# ECC_AGGR5_ECC_AGGR register map
Vendor: Texas Instruments
Peripheral module from a debugger description file (folder J721S2).
Registers are 32-bit, access not given, reset 0x0 unless marked. A register's access mark holds for its fields unless they carry their own. Offsets are as the file gives them; lines under a group give offsets from that group; [hi:lo] are bit positions; {n}, {i} and the like mark numbered series; 'fields as' and 'values as' point back to an identical list; <NAME> marks a mode.

## ECC_AGGR5_ECC_AGGR
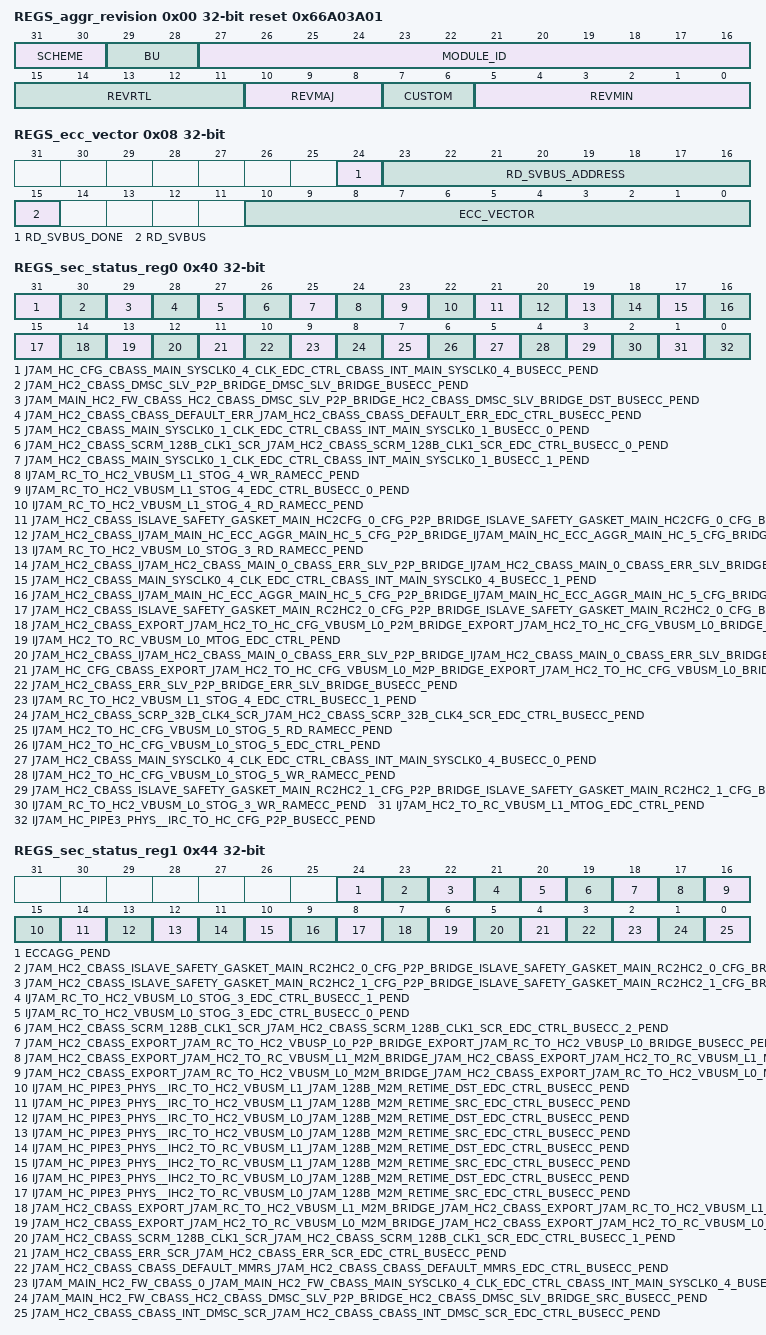
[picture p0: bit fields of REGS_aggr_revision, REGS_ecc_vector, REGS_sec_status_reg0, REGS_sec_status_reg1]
0x00 REGS_aggr_revision ro reset 0x66A03A01 — Revision parameters
  [31:30] SCHEME
  [29:28] BU
  [27:16] MODULE_ID
  [15:11] REVRTL — RTL version
  [10:8] REVMAJ — Major version
  [7:6] CUSTOM — Custom version
  [5:0] REVMIN — Minor version
0x08 REGS_ecc_vector — ECC Vector Register
  [24] RD_SVBUS_DONE — Status to indicate if read on serial VBUS is complete, write of any value will clear this bit. (access R/W1TC)
  [23:16] RD_SVBUS_ADDRESS rw — Read address
  [15] RD_SVBUS — Write 1 to trigger a read on the serial VBUS (access R/W1TS)
  [10:0] ECC_VECTOR rw — Value written to select the corresponding ECC RAM for control or status
0x0C REGS_misc_status ro reset 0x39 — Misc Status
  [10:0] NUM_RAMS — Indicates the number of RAMS serviced by the ECC aggregator
0x10 REGS_reserved_svbus rw — Reference other documents that contain the ECC RAM wrapper and EDC controller serial vbus register sets.
  [31:0] DATA — Serial VBUS register data
0x3C REGS_sec_eoi_reg — EOI Register
  [0] EOI_WR — EOI Register (access R/W1TS)
0x40 REGS_sec_status_reg0 — Interrupt Status Register 0
  [31] J7AM_HC_CFG_CBASS_MAIN_SYSCLK0_4_CLK_EDC_CTRL_CBASS_INT_MAIN_SYSCLK0_4_BUSECC_PEND — Interrupt Pending Status for j7am_hc_cfg_cbass_main_SYSCLK0_4_clk_edc_ctrl_cbass_int_main_SYSCLK0_4_busecc_pend (access R/W1TS)
  [30] J7AM_HC2_CBASS_DMSC_SLV_P2P_BRIDGE_DMSC_SLV_BRIDGE_BUSECC_PEND — Interrupt Pending Status for j7am_hc2_cbass_dmsc_slv_p2p_bridge_dmsc_slv_bridge_busecc_pend (access R/W1TS)
  [29] J7AM_MAIN_HC2_FW_CBASS_HC2_CBASS_DMSC_SLV_P2P_BRIDGE_HC2_CBASS_DMSC_SLV_BRIDGE_DST_BUSECC_PEND — Interrupt Pending Status for j7am_main_hc2_fw_cbass_hc2_cbass_dmsc_slv_p2p_bridge_hc2_cbass_dmsc_slv_bridge_dst_busecc_pend (access R/W1TS)
  [28] J7AM_HC2_CBASS_CBASS_DEFAULT_ERR_J7AM_HC2_CBASS_CBASS_DEFAULT_ERR_EDC_CTRL_BUSECC_PEND — Interrupt Pending Status for j7am_hc2_cbass_cbass_default_err_j7am_hc2_cbass_cbass_default_err_edc_ctrl_busecc_pend (access R/W1TS)
  [27] J7AM_HC2_CBASS_MAIN_SYSCLK0_1_CLK_EDC_CTRL_CBASS_INT_MAIN_SYSCLK0_1_BUSECC_0_PEND — Interrupt Pending Status for j7am_hc2_cbass_main_SYSCLK0_1_clk_edc_ctrl_cbass_int_main_SYSCLK0_1_busecc_0_pend (access R/W1TS)
  [26] J7AM_HC2_CBASS_SCRM_128B_CLK1_SCR_J7AM_HC2_CBASS_SCRM_128B_CLK1_SCR_EDC_CTRL_BUSECC_0_PEND — Interrupt Pending Status for j7am_hc2_cbass_scrm_128b_clk1_scr_j7am_hc2_cbass_scrm_128b_clk1_scr_edc_ctrl_busecc_0_pend (access R/W1TS)
  [25] J7AM_HC2_CBASS_MAIN_SYSCLK0_1_CLK_EDC_CTRL_CBASS_INT_MAIN_SYSCLK0_1_BUSECC_1_PEND — Interrupt Pending Status for j7am_hc2_cbass_main_SYSCLK0_1_clk_edc_ctrl_cbass_int_main_SYSCLK0_1_busecc_1_pend (access R/W1TS)
  [24] IJ7AM_RC_TO_HC2_VBUSM_L1_STOG_4_WR_RAMECC_PEND — Interrupt Pending Status for Ij7am_rc_to_hc2_vbusm_l1_stog_4_wr_ramecc_pend (access R/W1TS)
  [23] IJ7AM_RC_TO_HC2_VBUSM_L1_STOG_4_EDC_CTRL_BUSECC_0_PEND — Interrupt Pending Status for Ij7am_rc_to_hc2_vbusm_l1_stog_4_edc_ctrl_busecc_0_pend (access R/W1TS)
  [22] IJ7AM_RC_TO_HC2_VBUSM_L1_STOG_4_RD_RAMECC_PEND — Interrupt Pending Status for Ij7am_rc_to_hc2_vbusm_l1_stog_4_rd_ramecc_pend (access R/W1TS)
  [21] J7AM_HC2_CBASS_ISLAVE_SAFETY_GASKET_MAIN_HC2CFG_0_CFG_P2P_BRIDGE_ISLAVE_SAFETY_GASKET_MAIN_HC2CFG_0_CFG_BRIDGE_BUSECC_PEND — Interrupt Pending Status for j7am_hc2_cbass_Islave_safety_gasket_main_hc2cfg_0_cfg_p2p_bridge_Islave_safety_gasket_main_hc2cfg_0_cfg_bridge_busecc_pend (access R/W1TS)
  [20] J7AM_HC2_CBASS_IJ7AM_MAIN_HC_ECC_AGGR_MAIN_HC_5_CFG_P2P_BRIDGE_IJ7AM_MAIN_HC_ECC_AGGR_MAIN_HC_5_CFG_BRIDGE_DST_BUSECC_PEND — Interrupt Pending Status for j7am_hc2_cbass_Ij7am_main_hc_ecc_aggr_main_hc_5_cfg_p2p_bridge_Ij7am_main_hc_ecc_aggr_main_hc_5_cfg_bridge_dst_busecc_pend (access R/W1TS)
  [19] IJ7AM_RC_TO_HC2_VBUSM_L0_STOG_3_RD_RAMECC_PEND — Interrupt Pending Status for Ij7am_rc_to_hc2_vbusm_l0_stog_3_rd_ramecc_pend (access R/W1TS)
  [18] J7AM_HC2_CBASS_IJ7AM_HC2_CBASS_MAIN_0_CBASS_ERR_SLV_P2P_BRIDGE_IJ7AM_HC2_CBASS_MAIN_0_CBASS_ERR_SLV_BRIDGE_DST_BUSECC_PEND — Interrupt Pending Status for j7am_hc2_cbass_Ij7am_hc2_cbass_main_0_cbass_err_slv_p2p_bridge_Ij7am_hc2_cbass_main_0_cbass_err_slv_bridge_dst_busecc_pend (access R/W1TS)
  [17] J7AM_HC2_CBASS_MAIN_SYSCLK0_4_CLK_EDC_CTRL_CBASS_INT_MAIN_SYSCLK0_4_BUSECC_1_PEND — Interrupt Pending Status for j7am_hc2_cbass_main_SYSCLK0_4_clk_edc_ctrl_cbass_int_main_SYSCLK0_4_busecc_1_pend (access R/W1TS)
  [16] J7AM_HC2_CBASS_IJ7AM_MAIN_HC_ECC_AGGR_MAIN_HC_5_CFG_P2P_BRIDGE_IJ7AM_MAIN_HC_ECC_AGGR_MAIN_HC_5_CFG_BRIDGE_SRC_BUSECC_PEND — Interrupt Pending Status for j7am_hc2_cbass_Ij7am_main_hc_ecc_aggr_main_hc_5_cfg_p2p_bridge_Ij7am_main_hc_ecc_aggr_main_hc_5_cfg_bridge_src_busecc_pend (access R/W1TS)
  [15] J7AM_HC2_CBASS_ISLAVE_SAFETY_GASKET_MAIN_RC2HC2_0_CFG_P2P_BRIDGE_ISLAVE_SAFETY_GASKET_MAIN_RC2HC2_0_CFG_BRIDGE_SRC_BUSECC_PEND — Interrupt Pending Status for j7am_hc2_cbass_Islave_safety_gasket_main_rc2hc2_0_cfg_p2p_bridge_Islave_safety_gasket_main_rc2hc2_0_cfg_bridge_src_busecc_pend (access R/W1TS)
  [14] J7AM_HC2_CBASS_EXPORT_J7AM_HC2_TO_HC_CFG_VBUSM_L0_P2M_BRIDGE_EXPORT_J7AM_HC2_TO_HC_CFG_VBUSM_L0_BRIDGE_BUSECC_PEND — Interrupt Pending Status for j7am_hc2_cbass_export_j7am_hc2_to_hc_cfg_vbusm_l0_p2m_bridge_export_j7am_hc2_to_hc_cfg_vbusm_l0_bridge_busecc_pend (access R/W1TS)
  [13] IJ7AM_HC2_TO_RC_VBUSM_L0_MTOG_EDC_CTRL_PEND — Interrupt Pending Status for Ij7am_hc2_to_rc_vbusm_l0_mtog_edc_ctrl_pend (access R/W1TS)
  [12] J7AM_HC2_CBASS_IJ7AM_HC2_CBASS_MAIN_0_CBASS_ERR_SLV_P2P_BRIDGE_IJ7AM_HC2_CBASS_MAIN_0_CBASS_ERR_SLV_BRIDGE_SRC_BUSECC_PEND — Interrupt Pending Status for j7am_hc2_cbass_Ij7am_hc2_cbass_main_0_cbass_err_slv_p2p_bridge_Ij7am_hc2_cbass_main_0_cbass_err_slv_bridge_src_busecc_pend (access R/W1TS)
  [11] J7AM_HC_CFG_CBASS_EXPORT_J7AM_HC2_TO_HC_CFG_VBUSM_L0_M2P_BRIDGE_EXPORT_J7AM_HC2_TO_HC_CFG_VBUSM_L0_BRIDGE_BUSECC_PEND — Interrupt Pending Status for j7am_hc_cfg_cbass_export_j7am_hc2_to_hc_cfg_vbusm_l0_m2p_bridge_export_j7am_hc2_to_hc_cfg_vbusm_l0_bridge_busecc_pend (access R/W1TS)
  [10] J7AM_HC2_CBASS_ERR_SLV_P2P_BRIDGE_ERR_SLV_BRIDGE_BUSECC_PEND — Interrupt Pending Status for j7am_hc2_cbass_err_slv_p2p_bridge_err_slv_bridge_busecc_pend (access R/W1TS)
  [9] IJ7AM_RC_TO_HC2_VBUSM_L1_STOG_4_EDC_CTRL_BUSECC_1_PEND — Interrupt Pending Status for Ij7am_rc_to_hc2_vbusm_l1_stog_4_edc_ctrl_busecc_1_pend (access R/W1TS)
  [8] J7AM_HC2_CBASS_SCRP_32B_CLK4_SCR_J7AM_HC2_CBASS_SCRP_32B_CLK4_SCR_EDC_CTRL_BUSECC_PEND — Interrupt Pending Status for j7am_hc2_cbass_scrp_32b_clk4_scr_j7am_hc2_cbass_scrp_32b_clk4_scr_edc_ctrl_busecc_pend (access R/W1TS)
  [7] IJ7AM_HC2_TO_HC_CFG_VBUSM_L0_STOG_5_RD_RAMECC_PEND — Interrupt Pending Status for Ij7am_hc2_to_hc_cfg_vbusm_l0_stog_5_rd_ramecc_pend (access R/W1TS)
  [6] IJ7AM_HC2_TO_HC_CFG_VBUSM_L0_STOG_5_EDC_CTRL_PEND — Interrupt Pending Status for Ij7am_hc2_to_hc_cfg_vbusm_l0_stog_5_edc_ctrl_pend (access R/W1TS)
  [5] J7AM_HC2_CBASS_MAIN_SYSCLK0_4_CLK_EDC_CTRL_CBASS_INT_MAIN_SYSCLK0_4_BUSECC_0_PEND — Interrupt Pending Status for j7am_hc2_cbass_main_SYSCLK0_4_clk_edc_ctrl_cbass_int_main_SYSCLK0_4_busecc_0_pend (access R/W1TS)
  [4] IJ7AM_HC2_TO_HC_CFG_VBUSM_L0_STOG_5_WR_RAMECC_PEND — Interrupt Pending Status for Ij7am_hc2_to_hc_cfg_vbusm_l0_stog_5_wr_ramecc_pend (access R/W1TS)
  [3] J7AM_HC2_CBASS_ISLAVE_SAFETY_GASKET_MAIN_RC2HC2_1_CFG_P2P_BRIDGE_ISLAVE_SAFETY_GASKET_MAIN_RC2HC2_1_CFG_BRIDGE_SRC_BUSECC_PEND — Interrupt Pending Status for j7am_hc2_cbass_Islave_safety_gasket_main_rc2hc2_1_cfg_p2p_bridge_Islave_safety_gasket_main_rc2hc2_1_cfg_bridge_src_busecc_pend (access R/W1TS)
  [2] IJ7AM_RC_TO_HC2_VBUSM_L0_STOG_3_WR_RAMECC_PEND — Interrupt Pending Status for Ij7am_rc_to_hc2_vbusm_l0_stog_3_wr_ramecc_pend (access R/W1TS)
  [1] IJ7AM_HC2_TO_RC_VBUSM_L1_MTOG_EDC_CTRL_PEND — Interrupt Pending Status for Ij7am_hc2_to_rc_vbusm_l1_mtog_edc_ctrl_pend (access R/W1TS)
  [0] IJ7AM_HC_PIPE3_PHYS__IRC_TO_HC_CFG_P2P_BUSECC_PEND — Interrupt Pending Status for Ij7am_hc_pipe3_phys__Irc_to_hc_cfg_p2p_busecc_pend (access R/W1TS)
0x44 REGS_sec_status_reg1 — Interrupt Status Register 1
  [24] ECCAGG_PEND — Interrupt Pending Status for eccagg_pend (access R/W1TS)
  [23] J7AM_HC2_CBASS_ISLAVE_SAFETY_GASKET_MAIN_RC2HC2_0_CFG_P2P_BRIDGE_ISLAVE_SAFETY_GASKET_MAIN_RC2HC2_0_CFG_BRIDGE_DST_BUSECC_PEND — Interrupt Pending Status for j7am_hc2_cbass_Islave_safety_gasket_main_rc2hc2_0_cfg_p2p_bridge_Islave_safety_gasket_main_rc2hc2_0_cfg_bridge_dst_busecc_pend (access R/W1TS)
  [22] J7AM_HC2_CBASS_ISLAVE_SAFETY_GASKET_MAIN_RC2HC2_1_CFG_P2P_BRIDGE_ISLAVE_SAFETY_GASKET_MAIN_RC2HC2_1_CFG_BRIDGE_DST_BUSECC_PEND — Interrupt Pending Status for j7am_hc2_cbass_Islave_safety_gasket_main_rc2hc2_1_cfg_p2p_bridge_Islave_safety_gasket_main_rc2hc2_1_cfg_bridge_dst_busecc_pend (access R/W1TS)
  [21] IJ7AM_RC_TO_HC2_VBUSM_L0_STOG_3_EDC_CTRL_BUSECC_1_PEND — Interrupt Pending Status for Ij7am_rc_to_hc2_vbusm_l0_stog_3_edc_ctrl_busecc_1_pend (access R/W1TS)
  [20] IJ7AM_RC_TO_HC2_VBUSM_L0_STOG_3_EDC_CTRL_BUSECC_0_PEND — Interrupt Pending Status for Ij7am_rc_to_hc2_vbusm_l0_stog_3_edc_ctrl_busecc_0_pend (access R/W1TS)
  [19] J7AM_HC2_CBASS_SCRM_128B_CLK1_SCR_J7AM_HC2_CBASS_SCRM_128B_CLK1_SCR_EDC_CTRL_BUSECC_2_PEND — Interrupt Pending Status for j7am_hc2_cbass_scrm_128b_clk1_scr_j7am_hc2_cbass_scrm_128b_clk1_scr_edc_ctrl_busecc_2_pend (access R/W1TS)
  [18] J7AM_HC2_CBASS_EXPORT_J7AM_RC_TO_HC2_VBUSP_L0_P2P_BRIDGE_EXPORT_J7AM_RC_TO_HC2_VBUSP_L0_BRIDGE_BUSECC_PEND — Interrupt Pending Status for j7am_hc2_cbass_export_j7am_rc_to_hc2_vbusp_l0_p2p_bridge_export_j7am_rc_to_hc2_vbusp_l0_bridge_busecc_pend (access R/W1TS)
  [17] J7AM_HC2_CBASS_EXPORT_J7AM_HC2_TO_RC_VBUSM_L1_M2M_BRIDGE_J7AM_HC2_CBASS_EXPORT_J7AM_HC2_TO_RC_VBUSM_L1_M2M_BRIDGE_SRC_EDC_CTRL_BUSECC_PEND — Interrupt Pending Status for j7am_hc2_cbass_export_j7am_hc2_to_rc_vbusm_l1_m2m_bridge_j7am_hc2_cbass_export_j7am_hc2_to_rc_vbusm_l1_m2m_bridge_src_edc_ctrl_busecc_pend (access R/W1TS)
  [16] J7AM_HC2_CBASS_EXPORT_J7AM_RC_TO_HC2_VBUSM_L0_M2M_BRIDGE_J7AM_HC2_CBASS_EXPORT_J7AM_RC_TO_HC2_VBUSM_L0_M2M_BRIDGE_SRC_EDC_CTRL_BUSECC_PEND — Interrupt Pending Status for j7am_hc2_cbass_export_j7am_rc_to_hc2_vbusm_l0_m2m_bridge_j7am_hc2_cbass_export_j7am_rc_to_hc2_vbusm_l0_m2m_bridge_src_edc_ctrl_busecc_pend (access R/W1TS)
  [15] IJ7AM_HC_PIPE3_PHYS__IRC_TO_HC2_VBUSM_L1_J7AM_128B_M2M_RETIME_DST_EDC_CTRL_BUSECC_PEND — Interrupt Pending Status for Ij7am_hc_pipe3_phys__Irc_to_hc2_vbusm_l1_j7am_128b_m2m_retime_dst_edc_ctrl_busecc_pend (access R/W1TS)
  [14] IJ7AM_HC_PIPE3_PHYS__IRC_TO_HC2_VBUSM_L1_J7AM_128B_M2M_RETIME_SRC_EDC_CTRL_BUSECC_PEND — Interrupt Pending Status for Ij7am_hc_pipe3_phys__Irc_to_hc2_vbusm_l1_j7am_128b_m2m_retime_src_edc_ctrl_busecc_pend (access R/W1TS)
  [13] IJ7AM_HC_PIPE3_PHYS__IRC_TO_HC2_VBUSM_L0_J7AM_128B_M2M_RETIME_DST_EDC_CTRL_BUSECC_PEND — Interrupt Pending Status for Ij7am_hc_pipe3_phys__Irc_to_hc2_vbusm_l0_j7am_128b_m2m_retime_dst_edc_ctrl_busecc_pend (access R/W1TS)
  [12] IJ7AM_HC_PIPE3_PHYS__IRC_TO_HC2_VBUSM_L0_J7AM_128B_M2M_RETIME_SRC_EDC_CTRL_BUSECC_PEND — Interrupt Pending Status for Ij7am_hc_pipe3_phys__Irc_to_hc2_vbusm_l0_j7am_128b_m2m_retime_src_edc_ctrl_busecc_pend (access R/W1TS)
  [11] IJ7AM_HC_PIPE3_PHYS__IHC2_TO_RC_VBUSM_L1_J7AM_128B_M2M_RETIME_DST_EDC_CTRL_BUSECC_PEND — Interrupt Pending Status for Ij7am_hc_pipe3_phys__Ihc2_to_rc_vbusm_l1_j7am_128b_m2m_retime_dst_edc_ctrl_busecc_pend (access R/W1TS)
  [10] IJ7AM_HC_PIPE3_PHYS__IHC2_TO_RC_VBUSM_L1_J7AM_128B_M2M_RETIME_SRC_EDC_CTRL_BUSECC_PEND — Interrupt Pending Status for Ij7am_hc_pipe3_phys__Ihc2_to_rc_vbusm_l1_j7am_128b_m2m_retime_src_edc_ctrl_busecc_pend (access R/W1TS)
  [9] IJ7AM_HC_PIPE3_PHYS__IHC2_TO_RC_VBUSM_L0_J7AM_128B_M2M_RETIME_DST_EDC_CTRL_BUSECC_PEND — Interrupt Pending Status for Ij7am_hc_pipe3_phys__Ihc2_to_rc_vbusm_l0_j7am_128b_m2m_retime_dst_edc_ctrl_busecc_pend (access R/W1TS)
  [8] IJ7AM_HC_PIPE3_PHYS__IHC2_TO_RC_VBUSM_L0_J7AM_128B_M2M_RETIME_SRC_EDC_CTRL_BUSECC_PEND — Interrupt Pending Status for Ij7am_hc_pipe3_phys__Ihc2_to_rc_vbusm_l0_j7am_128b_m2m_retime_src_edc_ctrl_busecc_pend (access R/W1TS)
  [7] J7AM_HC2_CBASS_EXPORT_J7AM_RC_TO_HC2_VBUSM_L1_M2M_BRIDGE_J7AM_HC2_CBASS_EXPORT_J7AM_RC_TO_HC2_VBUSM_L1_M2M_BRIDGE_SRC_EDC_CTRL_BUSECC_PEND — Interrupt Pending Status for j7am_hc2_cbass_export_j7am_rc_to_hc2_vbusm_l1_m2m_bridge_j7am_hc2_cbass_export_j7am_rc_to_hc2_vbusm_l1_m2m_bridge_src_edc_ctrl_busecc_pend (access R/W1TS)
  [6] J7AM_HC2_CBASS_EXPORT_J7AM_HC2_TO_RC_VBUSM_L0_M2M_BRIDGE_J7AM_HC2_CBASS_EXPORT_J7AM_HC2_TO_RC_VBUSM_L0_M2M_BRIDGE_SRC_EDC_CTRL_BUSECC_PEND — Interrupt Pending Status for j7am_hc2_cbass_export_j7am_hc2_to_rc_vbusm_l0_m2m_bridge_j7am_hc2_cbass_export_j7am_hc2_to_rc_vbusm_l0_m2m_bridge_src_edc_ctrl_busecc_pend (access R/W1TS)
  [5] J7AM_HC2_CBASS_SCRM_128B_CLK1_SCR_J7AM_HC2_CBASS_SCRM_128B_CLK1_SCR_EDC_CTRL_BUSECC_1_PEND — Interrupt Pending Status for j7am_hc2_cbass_scrm_128b_clk1_scr_j7am_hc2_cbass_scrm_128b_clk1_scr_edc_ctrl_busecc_1_pend (access R/W1TS)
  [4] J7AM_HC2_CBASS_ERR_SCR_J7AM_HC2_CBASS_ERR_SCR_EDC_CTRL_BUSECC_PEND — Interrupt Pending Status for j7am_hc2_cbass_err_scr_j7am_hc2_cbass_err_scr_edc_ctrl_busecc_pend (access R/W1TS)
  [3] J7AM_HC2_CBASS_CBASS_DEFAULT_MMRS_J7AM_HC2_CBASS_CBASS_DEFAULT_MMRS_EDC_CTRL_BUSECC_PEND — Interrupt Pending Status for j7am_hc2_cbass_cbass_default_mmrs_j7am_hc2_cbass_cbass_default_mmrs_edc_ctrl_busecc_pend (access R/W1TS)
  [2] IJ7AM_MAIN_HC2_FW_CBASS_0_J7AM_MAIN_HC2_FW_CBASS_MAIN_SYSCLK0_4_CLK_EDC_CTRL_CBASS_INT_MAIN_SYSCLK0_4_BUSECC_PEND — Interrupt Pending Status for Ij7am_main_hc2_fw_cbass_0_j7am_main_hc2_fw_cbass_main_SYSCLK0_4_clk_edc_ctrl_cbass_int_main_SYSCLK0_4_busecc_pend (access R/W1TS)
  [1] J7AM_MAIN_HC2_FW_CBASS_HC2_CBASS_DMSC_SLV_P2P_BRIDGE_HC2_CBASS_DMSC_SLV_BRIDGE_SRC_BUSECC_PEND — Interrupt Pending Status for j7am_main_hc2_fw_cbass_hc2_cbass_dmsc_slv_p2p_bridge_hc2_cbass_dmsc_slv_bridge_src_busecc_pend (access R/W1TS)
  [0] J7AM_HC2_CBASS_CBASS_INT_DMSC_SCR_J7AM_HC2_CBASS_CBASS_INT_DMSC_SCR_EDC_CTRL_BUSECC_PEND — Interrupt Pending Status for j7am_hc2_cbass_cbass_int_dmsc_scr_j7am_hc2_cbass_cbass_int_dmsc_scr_edc_ctrl_busecc_pend (access R/W1TS)
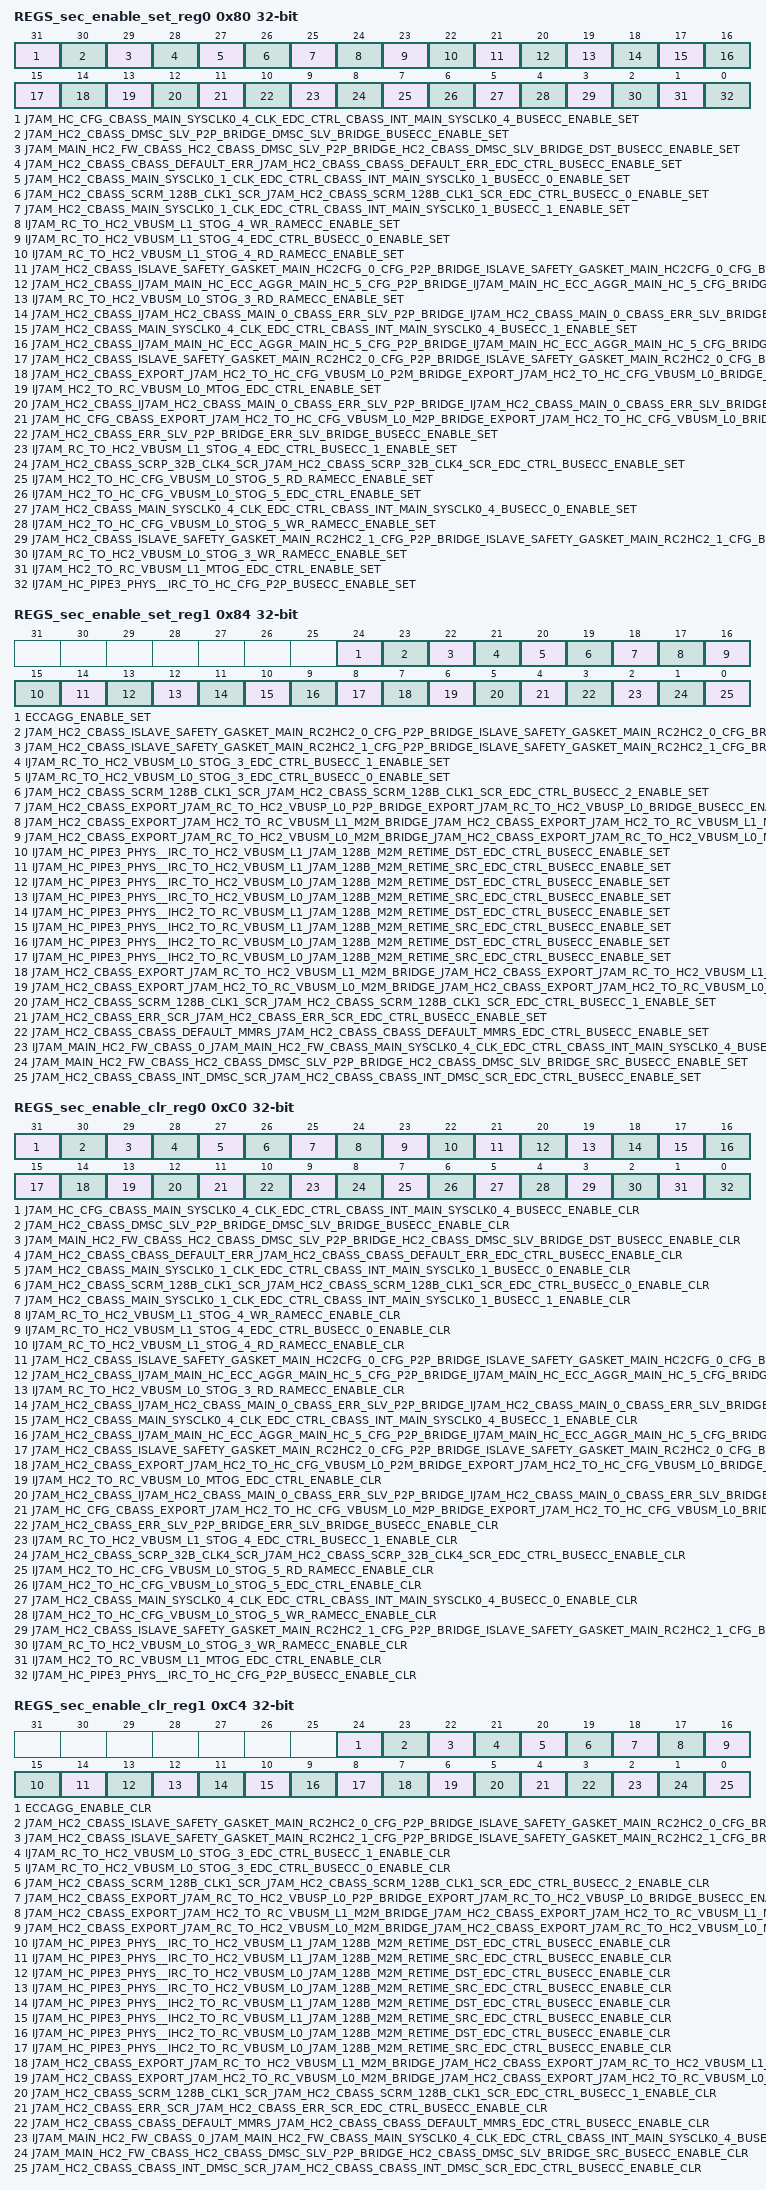
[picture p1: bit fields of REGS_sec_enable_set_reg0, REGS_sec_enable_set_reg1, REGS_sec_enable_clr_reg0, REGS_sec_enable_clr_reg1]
0x80 REGS_sec_enable_set_reg0 — Interrupt Enable Set Register 0
  [31] J7AM_HC_CFG_CBASS_MAIN_SYSCLK0_4_CLK_EDC_CTRL_CBASS_INT_MAIN_SYSCLK0_4_BUSECC_ENABLE_SET — Interrupt Enable Set Register for j7am_hc_cfg_cbass_main_SYSCLK0_4_clk_edc_ctrl_cbass_int_main_SYSCLK0_4_busecc_pend (access R/W1TS)
  [30] J7AM_HC2_CBASS_DMSC_SLV_P2P_BRIDGE_DMSC_SLV_BRIDGE_BUSECC_ENABLE_SET — Interrupt Enable Set Register for j7am_hc2_cbass_dmsc_slv_p2p_bridge_dmsc_slv_bridge_busecc_pend (access R/W1TS)
  [29] J7AM_MAIN_HC2_FW_CBASS_HC2_CBASS_DMSC_SLV_P2P_BRIDGE_HC2_CBASS_DMSC_SLV_BRIDGE_DST_BUSECC_ENABLE_SET — Interrupt Enable Set Register for j7am_main_hc2_fw_cbass_hc2_cbass_dmsc_slv_p2p_bridge_hc2_cbass_dmsc_slv_bridge_dst_busecc_pend (access R/W1TS)
  [28] J7AM_HC2_CBASS_CBASS_DEFAULT_ERR_J7AM_HC2_CBASS_CBASS_DEFAULT_ERR_EDC_CTRL_BUSECC_ENABLE_SET — Interrupt Enable Set Register for j7am_hc2_cbass_cbass_default_err_j7am_hc2_cbass_cbass_default_err_edc_ctrl_busecc_pend (access R/W1TS)
  [27] J7AM_HC2_CBASS_MAIN_SYSCLK0_1_CLK_EDC_CTRL_CBASS_INT_MAIN_SYSCLK0_1_BUSECC_0_ENABLE_SET — Interrupt Enable Set Register for j7am_hc2_cbass_main_SYSCLK0_1_clk_edc_ctrl_cbass_int_main_SYSCLK0_1_busecc_0_pend (access R/W1TS)
  [26] J7AM_HC2_CBASS_SCRM_128B_CLK1_SCR_J7AM_HC2_CBASS_SCRM_128B_CLK1_SCR_EDC_CTRL_BUSECC_0_ENABLE_SET — Interrupt Enable Set Register for j7am_hc2_cbass_scrm_128b_clk1_scr_j7am_hc2_cbass_scrm_128b_clk1_scr_edc_ctrl_busecc_0_pend (access R/W1TS)
  [25] J7AM_HC2_CBASS_MAIN_SYSCLK0_1_CLK_EDC_CTRL_CBASS_INT_MAIN_SYSCLK0_1_BUSECC_1_ENABLE_SET — Interrupt Enable Set Register for j7am_hc2_cbass_main_SYSCLK0_1_clk_edc_ctrl_cbass_int_main_SYSCLK0_1_busecc_1_pend (access R/W1TS)
  [24] IJ7AM_RC_TO_HC2_VBUSM_L1_STOG_4_WR_RAMECC_ENABLE_SET — Interrupt Enable Set Register for Ij7am_rc_to_hc2_vbusm_l1_stog_4_wr_ramecc_pend (access R/W1TS)
  [23] IJ7AM_RC_TO_HC2_VBUSM_L1_STOG_4_EDC_CTRL_BUSECC_0_ENABLE_SET — Interrupt Enable Set Register for Ij7am_rc_to_hc2_vbusm_l1_stog_4_edc_ctrl_busecc_0_pend (access R/W1TS)
  [22] IJ7AM_RC_TO_HC2_VBUSM_L1_STOG_4_RD_RAMECC_ENABLE_SET — Interrupt Enable Set Register for Ij7am_rc_to_hc2_vbusm_l1_stog_4_rd_ramecc_pend (access R/W1TS)
  [21] J7AM_HC2_CBASS_ISLAVE_SAFETY_GASKET_MAIN_HC2CFG_0_CFG_P2P_BRIDGE_ISLAVE_SAFETY_GASKET_MAIN_HC2CFG_0_CFG_BRIDGE_BUSECC_ENABLE_SET — Interrupt Enable Set Register for j7am_hc2_cbass_Islave_safety_gasket_main_hc2cfg_0_cfg_p2p_bridge_Islave_safety_gasket_main_hc2cfg_0_cfg_bridge_busecc_pend (access R/W1TS)
  [20] J7AM_HC2_CBASS_IJ7AM_MAIN_HC_ECC_AGGR_MAIN_HC_5_CFG_P2P_BRIDGE_IJ7AM_MAIN_HC_ECC_AGGR_MAIN_HC_5_CFG_BRIDGE_DST_BUSECC_ENABLE_SET — Interrupt Enable Set Register for j7am_hc2_cbass_Ij7am_main_hc_ecc_aggr_main_hc_5_cfg_p2p_bridge_Ij7am_main_hc_ecc_aggr_main_hc_5_cfg_bridge_dst_busecc_pend (access R/W1TS)
  [19] IJ7AM_RC_TO_HC2_VBUSM_L0_STOG_3_RD_RAMECC_ENABLE_SET — Interrupt Enable Set Register for Ij7am_rc_to_hc2_vbusm_l0_stog_3_rd_ramecc_pend (access R/W1TS)
  [18] J7AM_HC2_CBASS_IJ7AM_HC2_CBASS_MAIN_0_CBASS_ERR_SLV_P2P_BRIDGE_IJ7AM_HC2_CBASS_MAIN_0_CBASS_ERR_SLV_BRIDGE_DST_BUSECC_ENABLE_SET — Interrupt Enable Set Register for j7am_hc2_cbass_Ij7am_hc2_cbass_main_0_cbass_err_slv_p2p_bridge_Ij7am_hc2_cbass_main_0_cbass_err_slv_bridge_dst_busecc_pend (access R/W1TS)
  [17] J7AM_HC2_CBASS_MAIN_SYSCLK0_4_CLK_EDC_CTRL_CBASS_INT_MAIN_SYSCLK0_4_BUSECC_1_ENABLE_SET — Interrupt Enable Set Register for j7am_hc2_cbass_main_SYSCLK0_4_clk_edc_ctrl_cbass_int_main_SYSCLK0_4_busecc_1_pend (access R/W1TS)
  [16] J7AM_HC2_CBASS_IJ7AM_MAIN_HC_ECC_AGGR_MAIN_HC_5_CFG_P2P_BRIDGE_IJ7AM_MAIN_HC_ECC_AGGR_MAIN_HC_5_CFG_BRIDGE_SRC_BUSECC_ENABLE_SET — Interrupt Enable Set Register for j7am_hc2_cbass_Ij7am_main_hc_ecc_aggr_main_hc_5_cfg_p2p_bridge_Ij7am_main_hc_ecc_aggr_main_hc_5_cfg_bridge_src_busecc_pend (access R/W1TS)
  [15] J7AM_HC2_CBASS_ISLAVE_SAFETY_GASKET_MAIN_RC2HC2_0_CFG_P2P_BRIDGE_ISLAVE_SAFETY_GASKET_MAIN_RC2HC2_0_CFG_BRIDGE_SRC_BUSECC_ENABLE_SET — Interrupt Enable Set Register for j7am_hc2_cbass_Islave_safety_gasket_main_rc2hc2_0_cfg_p2p_bridge_Islave_safety_gasket_main_rc2hc2_0_cfg_bridge_src_busecc_pend (access R/W1TS)
  [14] J7AM_HC2_CBASS_EXPORT_J7AM_HC2_TO_HC_CFG_VBUSM_L0_P2M_BRIDGE_EXPORT_J7AM_HC2_TO_HC_CFG_VBUSM_L0_BRIDGE_BUSECC_ENABLE_SET — Interrupt Enable Set Register for j7am_hc2_cbass_export_j7am_hc2_to_hc_cfg_vbusm_l0_p2m_bridge_export_j7am_hc2_to_hc_cfg_vbusm_l0_bridge_busecc_pend (access R/W1TS)
  [13] IJ7AM_HC2_TO_RC_VBUSM_L0_MTOG_EDC_CTRL_ENABLE_SET — Interrupt Enable Set Register for Ij7am_hc2_to_rc_vbusm_l0_mtog_edc_ctrl_pend (access R/W1TS)
  [12] J7AM_HC2_CBASS_IJ7AM_HC2_CBASS_MAIN_0_CBASS_ERR_SLV_P2P_BRIDGE_IJ7AM_HC2_CBASS_MAIN_0_CBASS_ERR_SLV_BRIDGE_SRC_BUSECC_ENABLE_SET — Interrupt Enable Set Register for j7am_hc2_cbass_Ij7am_hc2_cbass_main_0_cbass_err_slv_p2p_bridge_Ij7am_hc2_cbass_main_0_cbass_err_slv_bridge_src_busecc_pend (access R/W1TS)
  [11] J7AM_HC_CFG_CBASS_EXPORT_J7AM_HC2_TO_HC_CFG_VBUSM_L0_M2P_BRIDGE_EXPORT_J7AM_HC2_TO_HC_CFG_VBUSM_L0_BRIDGE_BUSECC_ENABLE_SET — Interrupt Enable Set Register for j7am_hc_cfg_cbass_export_j7am_hc2_to_hc_cfg_vbusm_l0_m2p_bridge_export_j7am_hc2_to_hc_cfg_vbusm_l0_bridge_busecc_pend (access R/W1TS)
  [10] J7AM_HC2_CBASS_ERR_SLV_P2P_BRIDGE_ERR_SLV_BRIDGE_BUSECC_ENABLE_SET — Interrupt Enable Set Register for j7am_hc2_cbass_err_slv_p2p_bridge_err_slv_bridge_busecc_pend (access R/W1TS)
  [9] IJ7AM_RC_TO_HC2_VBUSM_L1_STOG_4_EDC_CTRL_BUSECC_1_ENABLE_SET — Interrupt Enable Set Register for Ij7am_rc_to_hc2_vbusm_l1_stog_4_edc_ctrl_busecc_1_pend (access R/W1TS)
  [8] J7AM_HC2_CBASS_SCRP_32B_CLK4_SCR_J7AM_HC2_CBASS_SCRP_32B_CLK4_SCR_EDC_CTRL_BUSECC_ENABLE_SET — Interrupt Enable Set Register for j7am_hc2_cbass_scrp_32b_clk4_scr_j7am_hc2_cbass_scrp_32b_clk4_scr_edc_ctrl_busecc_pend (access R/W1TS)
  [7] IJ7AM_HC2_TO_HC_CFG_VBUSM_L0_STOG_5_RD_RAMECC_ENABLE_SET — Interrupt Enable Set Register for Ij7am_hc2_to_hc_cfg_vbusm_l0_stog_5_rd_ramecc_pend (access R/W1TS)
  [6] IJ7AM_HC2_TO_HC_CFG_VBUSM_L0_STOG_5_EDC_CTRL_ENABLE_SET — Interrupt Enable Set Register for Ij7am_hc2_to_hc_cfg_vbusm_l0_stog_5_edc_ctrl_pend (access R/W1TS)
  [5] J7AM_HC2_CBASS_MAIN_SYSCLK0_4_CLK_EDC_CTRL_CBASS_INT_MAIN_SYSCLK0_4_BUSECC_0_ENABLE_SET — Interrupt Enable Set Register for j7am_hc2_cbass_main_SYSCLK0_4_clk_edc_ctrl_cbass_int_main_SYSCLK0_4_busecc_0_pend (access R/W1TS)
  [4] IJ7AM_HC2_TO_HC_CFG_VBUSM_L0_STOG_5_WR_RAMECC_ENABLE_SET — Interrupt Enable Set Register for Ij7am_hc2_to_hc_cfg_vbusm_l0_stog_5_wr_ramecc_pend (access R/W1TS)
  [3] J7AM_HC2_CBASS_ISLAVE_SAFETY_GASKET_MAIN_RC2HC2_1_CFG_P2P_BRIDGE_ISLAVE_SAFETY_GASKET_MAIN_RC2HC2_1_CFG_BRIDGE_SRC_BUSECC_ENABLE_SET — Interrupt Enable Set Register for j7am_hc2_cbass_Islave_safety_gasket_main_rc2hc2_1_cfg_p2p_bridge_Islave_safety_gasket_main_rc2hc2_1_cfg_bridge_src_busecc_pend (access R/W1TS)
  [2] IJ7AM_RC_TO_HC2_VBUSM_L0_STOG_3_WR_RAMECC_ENABLE_SET — Interrupt Enable Set Register for Ij7am_rc_to_hc2_vbusm_l0_stog_3_wr_ramecc_pend (access R/W1TS)
  [1] IJ7AM_HC2_TO_RC_VBUSM_L1_MTOG_EDC_CTRL_ENABLE_SET — Interrupt Enable Set Register for Ij7am_hc2_to_rc_vbusm_l1_mtog_edc_ctrl_pend (access R/W1TS)
  [0] IJ7AM_HC_PIPE3_PHYS__IRC_TO_HC_CFG_P2P_BUSECC_ENABLE_SET — Interrupt Enable Set Register for Ij7am_hc_pipe3_phys__Irc_to_hc_cfg_p2p_busecc_pend (access R/W1TS)
0x84 REGS_sec_enable_set_reg1 — Interrupt Enable Set Register 1
  [24] ECCAGG_ENABLE_SET — Interrupt Enable Set Register for eccagg_pend (access R/W1TS)
  [23] J7AM_HC2_CBASS_ISLAVE_SAFETY_GASKET_MAIN_RC2HC2_0_CFG_P2P_BRIDGE_ISLAVE_SAFETY_GASKET_MAIN_RC2HC2_0_CFG_BRIDGE_DST_BUSECC_ENABLE_SET — Interrupt Enable Set Register for j7am_hc2_cbass_Islave_safety_gasket_main_rc2hc2_0_cfg_p2p_bridge_Islave_safety_gasket_main_rc2hc2_0_cfg_bridge_dst_busecc_pend (access R/W1TS)
  [22] J7AM_HC2_CBASS_ISLAVE_SAFETY_GASKET_MAIN_RC2HC2_1_CFG_P2P_BRIDGE_ISLAVE_SAFETY_GASKET_MAIN_RC2HC2_1_CFG_BRIDGE_DST_BUSECC_ENABLE_SET — Interrupt Enable Set Register for j7am_hc2_cbass_Islave_safety_gasket_main_rc2hc2_1_cfg_p2p_bridge_Islave_safety_gasket_main_rc2hc2_1_cfg_bridge_dst_busecc_pend (access R/W1TS)
  [21] IJ7AM_RC_TO_HC2_VBUSM_L0_STOG_3_EDC_CTRL_BUSECC_1_ENABLE_SET — Interrupt Enable Set Register for Ij7am_rc_to_hc2_vbusm_l0_stog_3_edc_ctrl_busecc_1_pend (access R/W1TS)
  [20] IJ7AM_RC_TO_HC2_VBUSM_L0_STOG_3_EDC_CTRL_BUSECC_0_ENABLE_SET — Interrupt Enable Set Register for Ij7am_rc_to_hc2_vbusm_l0_stog_3_edc_ctrl_busecc_0_pend (access R/W1TS)
  [19] J7AM_HC2_CBASS_SCRM_128B_CLK1_SCR_J7AM_HC2_CBASS_SCRM_128B_CLK1_SCR_EDC_CTRL_BUSECC_2_ENABLE_SET — Interrupt Enable Set Register for j7am_hc2_cbass_scrm_128b_clk1_scr_j7am_hc2_cbass_scrm_128b_clk1_scr_edc_ctrl_busecc_2_pend (access R/W1TS)
  [18] J7AM_HC2_CBASS_EXPORT_J7AM_RC_TO_HC2_VBUSP_L0_P2P_BRIDGE_EXPORT_J7AM_RC_TO_HC2_VBUSP_L0_BRIDGE_BUSECC_ENABLE_SET — Interrupt Enable Set Register for j7am_hc2_cbass_export_j7am_rc_to_hc2_vbusp_l0_p2p_bridge_export_j7am_rc_to_hc2_vbusp_l0_bridge_busecc_pend (access R/W1TS)
  [17] J7AM_HC2_CBASS_EXPORT_J7AM_HC2_TO_RC_VBUSM_L1_M2M_BRIDGE_J7AM_HC2_CBASS_EXPORT_J7AM_HC2_TO_RC_VBUSM_L1_M2M_BRIDGE_SRC_EDC_CTRL_BUSECC_ENABLE_SET — Interrupt Enable Set Register for j7am_hc2_cbass_export_j7am_hc2_to_rc_vbusm_l1_m2m_bridge_j7am_hc2_cbass_export_j7am_hc2_to_rc_vbusm_l1_m2m_bridge_src_edc_ctrl_busecc_pend (access R/W1TS)
  [16] J7AM_HC2_CBASS_EXPORT_J7AM_RC_TO_HC2_VBUSM_L0_M2M_BRIDGE_J7AM_HC2_CBASS_EXPORT_J7AM_RC_TO_HC2_VBUSM_L0_M2M_BRIDGE_SRC_EDC_CTRL_BUSECC_ENABLE_SET — Interrupt Enable Set Register for j7am_hc2_cbass_export_j7am_rc_to_hc2_vbusm_l0_m2m_bridge_j7am_hc2_cbass_export_j7am_rc_to_hc2_vbusm_l0_m2m_bridge_src_edc_ctrl_busecc_pend (access R/W1TS)
  [15] IJ7AM_HC_PIPE3_PHYS__IRC_TO_HC2_VBUSM_L1_J7AM_128B_M2M_RETIME_DST_EDC_CTRL_BUSECC_ENABLE_SET — Interrupt Enable Set Register for Ij7am_hc_pipe3_phys__Irc_to_hc2_vbusm_l1_j7am_128b_m2m_retime_dst_edc_ctrl_busecc_pend (access R/W1TS)
  [14] IJ7AM_HC_PIPE3_PHYS__IRC_TO_HC2_VBUSM_L1_J7AM_128B_M2M_RETIME_SRC_EDC_CTRL_BUSECC_ENABLE_SET — Interrupt Enable Set Register for Ij7am_hc_pipe3_phys__Irc_to_hc2_vbusm_l1_j7am_128b_m2m_retime_src_edc_ctrl_busecc_pend (access R/W1TS)
  [13] IJ7AM_HC_PIPE3_PHYS__IRC_TO_HC2_VBUSM_L0_J7AM_128B_M2M_RETIME_DST_EDC_CTRL_BUSECC_ENABLE_SET — Interrupt Enable Set Register for Ij7am_hc_pipe3_phys__Irc_to_hc2_vbusm_l0_j7am_128b_m2m_retime_dst_edc_ctrl_busecc_pend (access R/W1TS)
  [12] IJ7AM_HC_PIPE3_PHYS__IRC_TO_HC2_VBUSM_L0_J7AM_128B_M2M_RETIME_SRC_EDC_CTRL_BUSECC_ENABLE_SET — Interrupt Enable Set Register for Ij7am_hc_pipe3_phys__Irc_to_hc2_vbusm_l0_j7am_128b_m2m_retime_src_edc_ctrl_busecc_pend (access R/W1TS)
  [11] IJ7AM_HC_PIPE3_PHYS__IHC2_TO_RC_VBUSM_L1_J7AM_128B_M2M_RETIME_DST_EDC_CTRL_BUSECC_ENABLE_SET — Interrupt Enable Set Register for Ij7am_hc_pipe3_phys__Ihc2_to_rc_vbusm_l1_j7am_128b_m2m_retime_dst_edc_ctrl_busecc_pend (access R/W1TS)
  [10] IJ7AM_HC_PIPE3_PHYS__IHC2_TO_RC_VBUSM_L1_J7AM_128B_M2M_RETIME_SRC_EDC_CTRL_BUSECC_ENABLE_SET — Interrupt Enable Set Register for Ij7am_hc_pipe3_phys__Ihc2_to_rc_vbusm_l1_j7am_128b_m2m_retime_src_edc_ctrl_busecc_pend (access R/W1TS)
  [9] IJ7AM_HC_PIPE3_PHYS__IHC2_TO_RC_VBUSM_L0_J7AM_128B_M2M_RETIME_DST_EDC_CTRL_BUSECC_ENABLE_SET — Interrupt Enable Set Register for Ij7am_hc_pipe3_phys__Ihc2_to_rc_vbusm_l0_j7am_128b_m2m_retime_dst_edc_ctrl_busecc_pend (access R/W1TS)
  [8] IJ7AM_HC_PIPE3_PHYS__IHC2_TO_RC_VBUSM_L0_J7AM_128B_M2M_RETIME_SRC_EDC_CTRL_BUSECC_ENABLE_SET — Interrupt Enable Set Register for Ij7am_hc_pipe3_phys__Ihc2_to_rc_vbusm_l0_j7am_128b_m2m_retime_src_edc_ctrl_busecc_pend (access R/W1TS)
  [7] J7AM_HC2_CBASS_EXPORT_J7AM_RC_TO_HC2_VBUSM_L1_M2M_BRIDGE_J7AM_HC2_CBASS_EXPORT_J7AM_RC_TO_HC2_VBUSM_L1_M2M_BRIDGE_SRC_EDC_CTRL_BUSECC_ENABLE_SET — Interrupt Enable Set Register for j7am_hc2_cbass_export_j7am_rc_to_hc2_vbusm_l1_m2m_bridge_j7am_hc2_cbass_export_j7am_rc_to_hc2_vbusm_l1_m2m_bridge_src_edc_ctrl_busecc_pend (access R/W1TS)
  [6] J7AM_HC2_CBASS_EXPORT_J7AM_HC2_TO_RC_VBUSM_L0_M2M_BRIDGE_J7AM_HC2_CBASS_EXPORT_J7AM_HC2_TO_RC_VBUSM_L0_M2M_BRIDGE_SRC_EDC_CTRL_BUSECC_ENABLE_SET — Interrupt Enable Set Register for j7am_hc2_cbass_export_j7am_hc2_to_rc_vbusm_l0_m2m_bridge_j7am_hc2_cbass_export_j7am_hc2_to_rc_vbusm_l0_m2m_bridge_src_edc_ctrl_busecc_pend (access R/W1TS)
  [5] J7AM_HC2_CBASS_SCRM_128B_CLK1_SCR_J7AM_HC2_CBASS_SCRM_128B_CLK1_SCR_EDC_CTRL_BUSECC_1_ENABLE_SET — Interrupt Enable Set Register for j7am_hc2_cbass_scrm_128b_clk1_scr_j7am_hc2_cbass_scrm_128b_clk1_scr_edc_ctrl_busecc_1_pend (access R/W1TS)
  [4] J7AM_HC2_CBASS_ERR_SCR_J7AM_HC2_CBASS_ERR_SCR_EDC_CTRL_BUSECC_ENABLE_SET — Interrupt Enable Set Register for j7am_hc2_cbass_err_scr_j7am_hc2_cbass_err_scr_edc_ctrl_busecc_pend (access R/W1TS)
  [3] J7AM_HC2_CBASS_CBASS_DEFAULT_MMRS_J7AM_HC2_CBASS_CBASS_DEFAULT_MMRS_EDC_CTRL_BUSECC_ENABLE_SET — Interrupt Enable Set Register for j7am_hc2_cbass_cbass_default_mmrs_j7am_hc2_cbass_cbass_default_mmrs_edc_ctrl_busecc_pend (access R/W1TS)
  [2] IJ7AM_MAIN_HC2_FW_CBASS_0_J7AM_MAIN_HC2_FW_CBASS_MAIN_SYSCLK0_4_CLK_EDC_CTRL_CBASS_INT_MAIN_SYSCLK0_4_BUSECC_ENABLE_SET — Interrupt Enable Set Register for Ij7am_main_hc2_fw_cbass_0_j7am_main_hc2_fw_cbass_main_SYSCLK0_4_clk_edc_ctrl_cbass_int_main_SYSCLK0_4_busecc_pend (access R/W1TS)
  [1] J7AM_MAIN_HC2_FW_CBASS_HC2_CBASS_DMSC_SLV_P2P_BRIDGE_HC2_CBASS_DMSC_SLV_BRIDGE_SRC_BUSECC_ENABLE_SET — Interrupt Enable Set Register for j7am_main_hc2_fw_cbass_hc2_cbass_dmsc_slv_p2p_bridge_hc2_cbass_dmsc_slv_bridge_src_busecc_pend (access R/W1TS)
  [0] J7AM_HC2_CBASS_CBASS_INT_DMSC_SCR_J7AM_HC2_CBASS_CBASS_INT_DMSC_SCR_EDC_CTRL_BUSECC_ENABLE_SET — Interrupt Enable Set Register for j7am_hc2_cbass_cbass_int_dmsc_scr_j7am_hc2_cbass_cbass_int_dmsc_scr_edc_ctrl_busecc_pend (access R/W1TS)
0xC0 REGS_sec_enable_clr_reg0 — Interrupt Enable Clear Register 0
  [31] J7AM_HC_CFG_CBASS_MAIN_SYSCLK0_4_CLK_EDC_CTRL_CBASS_INT_MAIN_SYSCLK0_4_BUSECC_ENABLE_CLR — Interrupt Enable Clear Register for j7am_hc_cfg_cbass_main_SYSCLK0_4_clk_edc_ctrl_cbass_int_main_SYSCLK0_4_busecc_pend (access R/W1TC)
  [30] J7AM_HC2_CBASS_DMSC_SLV_P2P_BRIDGE_DMSC_SLV_BRIDGE_BUSECC_ENABLE_CLR — Interrupt Enable Clear Register for j7am_hc2_cbass_dmsc_slv_p2p_bridge_dmsc_slv_bridge_busecc_pend (access R/W1TC)
  [29] J7AM_MAIN_HC2_FW_CBASS_HC2_CBASS_DMSC_SLV_P2P_BRIDGE_HC2_CBASS_DMSC_SLV_BRIDGE_DST_BUSECC_ENABLE_CLR — Interrupt Enable Clear Register for j7am_main_hc2_fw_cbass_hc2_cbass_dmsc_slv_p2p_bridge_hc2_cbass_dmsc_slv_bridge_dst_busecc_pend (access R/W1TC)
  [28] J7AM_HC2_CBASS_CBASS_DEFAULT_ERR_J7AM_HC2_CBASS_CBASS_DEFAULT_ERR_EDC_CTRL_BUSECC_ENABLE_CLR — Interrupt Enable Clear Register for j7am_hc2_cbass_cbass_default_err_j7am_hc2_cbass_cbass_default_err_edc_ctrl_busecc_pend (access R/W1TC)
  [27] J7AM_HC2_CBASS_MAIN_SYSCLK0_1_CLK_EDC_CTRL_CBASS_INT_MAIN_SYSCLK0_1_BUSECC_0_ENABLE_CLR — Interrupt Enable Clear Register for j7am_hc2_cbass_main_SYSCLK0_1_clk_edc_ctrl_cbass_int_main_SYSCLK0_1_busecc_0_pend (access R/W1TC)
  [26] J7AM_HC2_CBASS_SCRM_128B_CLK1_SCR_J7AM_HC2_CBASS_SCRM_128B_CLK1_SCR_EDC_CTRL_BUSECC_0_ENABLE_CLR — Interrupt Enable Clear Register for j7am_hc2_cbass_scrm_128b_clk1_scr_j7am_hc2_cbass_scrm_128b_clk1_scr_edc_ctrl_busecc_0_pend (access R/W1TC)
  [25] J7AM_HC2_CBASS_MAIN_SYSCLK0_1_CLK_EDC_CTRL_CBASS_INT_MAIN_SYSCLK0_1_BUSECC_1_ENABLE_CLR — Interrupt Enable Clear Register for j7am_hc2_cbass_main_SYSCLK0_1_clk_edc_ctrl_cbass_int_main_SYSCLK0_1_busecc_1_pend (access R/W1TC)
  [24] IJ7AM_RC_TO_HC2_VBUSM_L1_STOG_4_WR_RAMECC_ENABLE_CLR — Interrupt Enable Clear Register for Ij7am_rc_to_hc2_vbusm_l1_stog_4_wr_ramecc_pend (access R/W1TC)
  [23] IJ7AM_RC_TO_HC2_VBUSM_L1_STOG_4_EDC_CTRL_BUSECC_0_ENABLE_CLR — Interrupt Enable Clear Register for Ij7am_rc_to_hc2_vbusm_l1_stog_4_edc_ctrl_busecc_0_pend (access R/W1TC)
  [22] IJ7AM_RC_TO_HC2_VBUSM_L1_STOG_4_RD_RAMECC_ENABLE_CLR — Interrupt Enable Clear Register for Ij7am_rc_to_hc2_vbusm_l1_stog_4_rd_ramecc_pend (access R/W1TC)
  [21] J7AM_HC2_CBASS_ISLAVE_SAFETY_GASKET_MAIN_HC2CFG_0_CFG_P2P_BRIDGE_ISLAVE_SAFETY_GASKET_MAIN_HC2CFG_0_CFG_BRIDGE_BUSECC_ENABLE_CLR — Interrupt Enable Clear Register for j7am_hc2_cbass_Islave_safety_gasket_main_hc2cfg_0_cfg_p2p_bridge_Islave_safety_gasket_main_hc2cfg_0_cfg_bridge_busecc_pend (access R/W1TC)
  [20] J7AM_HC2_CBASS_IJ7AM_MAIN_HC_ECC_AGGR_MAIN_HC_5_CFG_P2P_BRIDGE_IJ7AM_MAIN_HC_ECC_AGGR_MAIN_HC_5_CFG_BRIDGE_DST_BUSECC_ENABLE_CLR — Interrupt Enable Clear Register for j7am_hc2_cbass_Ij7am_main_hc_ecc_aggr_main_hc_5_cfg_p2p_bridge_Ij7am_main_hc_ecc_aggr_main_hc_5_cfg_bridge_dst_busecc_pend (access R/W1TC)
  [19] IJ7AM_RC_TO_HC2_VBUSM_L0_STOG_3_RD_RAMECC_ENABLE_CLR — Interrupt Enable Clear Register for Ij7am_rc_to_hc2_vbusm_l0_stog_3_rd_ramecc_pend (access R/W1TC)
  [18] J7AM_HC2_CBASS_IJ7AM_HC2_CBASS_MAIN_0_CBASS_ERR_SLV_P2P_BRIDGE_IJ7AM_HC2_CBASS_MAIN_0_CBASS_ERR_SLV_BRIDGE_DST_BUSECC_ENABLE_CLR — Interrupt Enable Clear Register for j7am_hc2_cbass_Ij7am_hc2_cbass_main_0_cbass_err_slv_p2p_bridge_Ij7am_hc2_cbass_main_0_cbass_err_slv_bridge_dst_busecc_pend (access R/W1TC)
  [17] J7AM_HC2_CBASS_MAIN_SYSCLK0_4_CLK_EDC_CTRL_CBASS_INT_MAIN_SYSCLK0_4_BUSECC_1_ENABLE_CLR — Interrupt Enable Clear Register for j7am_hc2_cbass_main_SYSCLK0_4_clk_edc_ctrl_cbass_int_main_SYSCLK0_4_busecc_1_pend (access R/W1TC)
  [16] J7AM_HC2_CBASS_IJ7AM_MAIN_HC_ECC_AGGR_MAIN_HC_5_CFG_P2P_BRIDGE_IJ7AM_MAIN_HC_ECC_AGGR_MAIN_HC_5_CFG_BRIDGE_SRC_BUSECC_ENABLE_CLR — Interrupt Enable Clear Register for j7am_hc2_cbass_Ij7am_main_hc_ecc_aggr_main_hc_5_cfg_p2p_bridge_Ij7am_main_hc_ecc_aggr_main_hc_5_cfg_bridge_src_busecc_pend (access R/W1TC)
  [15] J7AM_HC2_CBASS_ISLAVE_SAFETY_GASKET_MAIN_RC2HC2_0_CFG_P2P_BRIDGE_ISLAVE_SAFETY_GASKET_MAIN_RC2HC2_0_CFG_BRIDGE_SRC_BUSECC_ENABLE_CLR — Interrupt Enable Clear Register for j7am_hc2_cbass_Islave_safety_gasket_main_rc2hc2_0_cfg_p2p_bridge_Islave_safety_gasket_main_rc2hc2_0_cfg_bridge_src_busecc_pend (access R/W1TC)
  [14] J7AM_HC2_CBASS_EXPORT_J7AM_HC2_TO_HC_CFG_VBUSM_L0_P2M_BRIDGE_EXPORT_J7AM_HC2_TO_HC_CFG_VBUSM_L0_BRIDGE_BUSECC_ENABLE_CLR — Interrupt Enable Clear Register for j7am_hc2_cbass_export_j7am_hc2_to_hc_cfg_vbusm_l0_p2m_bridge_export_j7am_hc2_to_hc_cfg_vbusm_l0_bridge_busecc_pend (access R/W1TC)
  [13] IJ7AM_HC2_TO_RC_VBUSM_L0_MTOG_EDC_CTRL_ENABLE_CLR — Interrupt Enable Clear Register for Ij7am_hc2_to_rc_vbusm_l0_mtog_edc_ctrl_pend (access R/W1TC)
  [12] J7AM_HC2_CBASS_IJ7AM_HC2_CBASS_MAIN_0_CBASS_ERR_SLV_P2P_BRIDGE_IJ7AM_HC2_CBASS_MAIN_0_CBASS_ERR_SLV_BRIDGE_SRC_BUSECC_ENABLE_CLR — Interrupt Enable Clear Register for j7am_hc2_cbass_Ij7am_hc2_cbass_main_0_cbass_err_slv_p2p_bridge_Ij7am_hc2_cbass_main_0_cbass_err_slv_bridge_src_busecc_pend (access R/W1TC)
  [11] J7AM_HC_CFG_CBASS_EXPORT_J7AM_HC2_TO_HC_CFG_VBUSM_L0_M2P_BRIDGE_EXPORT_J7AM_HC2_TO_HC_CFG_VBUSM_L0_BRIDGE_BUSECC_ENABLE_CLR — Interrupt Enable Clear Register for j7am_hc_cfg_cbass_export_j7am_hc2_to_hc_cfg_vbusm_l0_m2p_bridge_export_j7am_hc2_to_hc_cfg_vbusm_l0_bridge_busecc_pend (access R/W1TC)
  [10] J7AM_HC2_CBASS_ERR_SLV_P2P_BRIDGE_ERR_SLV_BRIDGE_BUSECC_ENABLE_CLR — Interrupt Enable Clear Register for j7am_hc2_cbass_err_slv_p2p_bridge_err_slv_bridge_busecc_pend (access R/W1TC)
  [9] IJ7AM_RC_TO_HC2_VBUSM_L1_STOG_4_EDC_CTRL_BUSECC_1_ENABLE_CLR — Interrupt Enable Clear Register for Ij7am_rc_to_hc2_vbusm_l1_stog_4_edc_ctrl_busecc_1_pend (access R/W1TC)
  [8] J7AM_HC2_CBASS_SCRP_32B_CLK4_SCR_J7AM_HC2_CBASS_SCRP_32B_CLK4_SCR_EDC_CTRL_BUSECC_ENABLE_CLR — Interrupt Enable Clear Register for j7am_hc2_cbass_scrp_32b_clk4_scr_j7am_hc2_cbass_scrp_32b_clk4_scr_edc_ctrl_busecc_pend (access R/W1TC)
  [7] IJ7AM_HC2_TO_HC_CFG_VBUSM_L0_STOG_5_RD_RAMECC_ENABLE_CLR — Interrupt Enable Clear Register for Ij7am_hc2_to_hc_cfg_vbusm_l0_stog_5_rd_ramecc_pend (access R/W1TC)
  [6] IJ7AM_HC2_TO_HC_CFG_VBUSM_L0_STOG_5_EDC_CTRL_ENABLE_CLR — Interrupt Enable Clear Register for Ij7am_hc2_to_hc_cfg_vbusm_l0_stog_5_edc_ctrl_pend (access R/W1TC)
  [5] J7AM_HC2_CBASS_MAIN_SYSCLK0_4_CLK_EDC_CTRL_CBASS_INT_MAIN_SYSCLK0_4_BUSECC_0_ENABLE_CLR — Interrupt Enable Clear Register for j7am_hc2_cbass_main_SYSCLK0_4_clk_edc_ctrl_cbass_int_main_SYSCLK0_4_busecc_0_pend (access R/W1TC)
  [4] IJ7AM_HC2_TO_HC_CFG_VBUSM_L0_STOG_5_WR_RAMECC_ENABLE_CLR — Interrupt Enable Clear Register for Ij7am_hc2_to_hc_cfg_vbusm_l0_stog_5_wr_ramecc_pend (access R/W1TC)
  [3] J7AM_HC2_CBASS_ISLAVE_SAFETY_GASKET_MAIN_RC2HC2_1_CFG_P2P_BRIDGE_ISLAVE_SAFETY_GASKET_MAIN_RC2HC2_1_CFG_BRIDGE_SRC_BUSECC_ENABLE_CLR — Interrupt Enable Clear Register for j7am_hc2_cbass_Islave_safety_gasket_main_rc2hc2_1_cfg_p2p_bridge_Islave_safety_gasket_main_rc2hc2_1_cfg_bridge_src_busecc_pend (access R/W1TC)
  [2] IJ7AM_RC_TO_HC2_VBUSM_L0_STOG_3_WR_RAMECC_ENABLE_CLR — Interrupt Enable Clear Register for Ij7am_rc_to_hc2_vbusm_l0_stog_3_wr_ramecc_pend (access R/W1TC)
  [1] IJ7AM_HC2_TO_RC_VBUSM_L1_MTOG_EDC_CTRL_ENABLE_CLR — Interrupt Enable Clear Register for Ij7am_hc2_to_rc_vbusm_l1_mtog_edc_ctrl_pend (access R/W1TC)
  [0] IJ7AM_HC_PIPE3_PHYS__IRC_TO_HC_CFG_P2P_BUSECC_ENABLE_CLR — Interrupt Enable Clear Register for Ij7am_hc_pipe3_phys__Irc_to_hc_cfg_p2p_busecc_pend (access R/W1TC)
0xC4 REGS_sec_enable_clr_reg1 — Interrupt Enable Clear Register 1
  [24] ECCAGG_ENABLE_CLR — Interrupt Enable Clear Register for eccagg_pend (access R/W1TC)
  [23] J7AM_HC2_CBASS_ISLAVE_SAFETY_GASKET_MAIN_RC2HC2_0_CFG_P2P_BRIDGE_ISLAVE_SAFETY_GASKET_MAIN_RC2HC2_0_CFG_BRIDGE_DST_BUSECC_ENABLE_CLR — Interrupt Enable Clear Register for j7am_hc2_cbass_Islave_safety_gasket_main_rc2hc2_0_cfg_p2p_bridge_Islave_safety_gasket_main_rc2hc2_0_cfg_bridge_dst_busecc_pend (access R/W1TC)
  [22] J7AM_HC2_CBASS_ISLAVE_SAFETY_GASKET_MAIN_RC2HC2_1_CFG_P2P_BRIDGE_ISLAVE_SAFETY_GASKET_MAIN_RC2HC2_1_CFG_BRIDGE_DST_BUSECC_ENABLE_CLR — Interrupt Enable Clear Register for j7am_hc2_cbass_Islave_safety_gasket_main_rc2hc2_1_cfg_p2p_bridge_Islave_safety_gasket_main_rc2hc2_1_cfg_bridge_dst_busecc_pend (access R/W1TC)
  [21] IJ7AM_RC_TO_HC2_VBUSM_L0_STOG_3_EDC_CTRL_BUSECC_1_ENABLE_CLR — Interrupt Enable Clear Register for Ij7am_rc_to_hc2_vbusm_l0_stog_3_edc_ctrl_busecc_1_pend (access R/W1TC)
  [20] IJ7AM_RC_TO_HC2_VBUSM_L0_STOG_3_EDC_CTRL_BUSECC_0_ENABLE_CLR — Interrupt Enable Clear Register for Ij7am_rc_to_hc2_vbusm_l0_stog_3_edc_ctrl_busecc_0_pend (access R/W1TC)
  [19] J7AM_HC2_CBASS_SCRM_128B_CLK1_SCR_J7AM_HC2_CBASS_SCRM_128B_CLK1_SCR_EDC_CTRL_BUSECC_2_ENABLE_CLR — Interrupt Enable Clear Register for j7am_hc2_cbass_scrm_128b_clk1_scr_j7am_hc2_cbass_scrm_128b_clk1_scr_edc_ctrl_busecc_2_pend (access R/W1TC)
  [18] J7AM_HC2_CBASS_EXPORT_J7AM_RC_TO_HC2_VBUSP_L0_P2P_BRIDGE_EXPORT_J7AM_RC_TO_HC2_VBUSP_L0_BRIDGE_BUSECC_ENABLE_CLR — Interrupt Enable Clear Register for j7am_hc2_cbass_export_j7am_rc_to_hc2_vbusp_l0_p2p_bridge_export_j7am_rc_to_hc2_vbusp_l0_bridge_busecc_pend (access R/W1TC)
  [17] J7AM_HC2_CBASS_EXPORT_J7AM_HC2_TO_RC_VBUSM_L1_M2M_BRIDGE_J7AM_HC2_CBASS_EXPORT_J7AM_HC2_TO_RC_VBUSM_L1_M2M_BRIDGE_SRC_EDC_CTRL_BUSECC_ENABLE_CLR — Interrupt Enable Clear Register for j7am_hc2_cbass_export_j7am_hc2_to_rc_vbusm_l1_m2m_bridge_j7am_hc2_cbass_export_j7am_hc2_to_rc_vbusm_l1_m2m_bridge_src_edc_ctrl_busecc_pend (access R/W1TC)
  [16] J7AM_HC2_CBASS_EXPORT_J7AM_RC_TO_HC2_VBUSM_L0_M2M_BRIDGE_J7AM_HC2_CBASS_EXPORT_J7AM_RC_TO_HC2_VBUSM_L0_M2M_BRIDGE_SRC_EDC_CTRL_BUSECC_ENABLE_CLR — Interrupt Enable Clear Register for j7am_hc2_cbass_export_j7am_rc_to_hc2_vbusm_l0_m2m_bridge_j7am_hc2_cbass_export_j7am_rc_to_hc2_vbusm_l0_m2m_bridge_src_edc_ctrl_busecc_pend (access R/W1TC)
  [15] IJ7AM_HC_PIPE3_PHYS__IRC_TO_HC2_VBUSM_L1_J7AM_128B_M2M_RETIME_DST_EDC_CTRL_BUSECC_ENABLE_CLR — Interrupt Enable Clear Register for Ij7am_hc_pipe3_phys__Irc_to_hc2_vbusm_l1_j7am_128b_m2m_retime_dst_edc_ctrl_busecc_pend (access R/W1TC)
  [14] IJ7AM_HC_PIPE3_PHYS__IRC_TO_HC2_VBUSM_L1_J7AM_128B_M2M_RETIME_SRC_EDC_CTRL_BUSECC_ENABLE_CLR — Interrupt Enable Clear Register for Ij7am_hc_pipe3_phys__Irc_to_hc2_vbusm_l1_j7am_128b_m2m_retime_src_edc_ctrl_busecc_pend (access R/W1TC)
  [13] IJ7AM_HC_PIPE3_PHYS__IRC_TO_HC2_VBUSM_L0_J7AM_128B_M2M_RETIME_DST_EDC_CTRL_BUSECC_ENABLE_CLR — Interrupt Enable Clear Register for Ij7am_hc_pipe3_phys__Irc_to_hc2_vbusm_l0_j7am_128b_m2m_retime_dst_edc_ctrl_busecc_pend (access R/W1TC)
  [12] IJ7AM_HC_PIPE3_PHYS__IRC_TO_HC2_VBUSM_L0_J7AM_128B_M2M_RETIME_SRC_EDC_CTRL_BUSECC_ENABLE_CLR — Interrupt Enable Clear Register for Ij7am_hc_pipe3_phys__Irc_to_hc2_vbusm_l0_j7am_128b_m2m_retime_src_edc_ctrl_busecc_pend (access R/W1TC)
  [11] IJ7AM_HC_PIPE3_PHYS__IHC2_TO_RC_VBUSM_L1_J7AM_128B_M2M_RETIME_DST_EDC_CTRL_BUSECC_ENABLE_CLR — Interrupt Enable Clear Register for Ij7am_hc_pipe3_phys__Ihc2_to_rc_vbusm_l1_j7am_128b_m2m_retime_dst_edc_ctrl_busecc_pend (access R/W1TC)
  [10] IJ7AM_HC_PIPE3_PHYS__IHC2_TO_RC_VBUSM_L1_J7AM_128B_M2M_RETIME_SRC_EDC_CTRL_BUSECC_ENABLE_CLR — Interrupt Enable Clear Register for Ij7am_hc_pipe3_phys__Ihc2_to_rc_vbusm_l1_j7am_128b_m2m_retime_src_edc_ctrl_busecc_pend (access R/W1TC)
  [9] IJ7AM_HC_PIPE3_PHYS__IHC2_TO_RC_VBUSM_L0_J7AM_128B_M2M_RETIME_DST_EDC_CTRL_BUSECC_ENABLE_CLR — Interrupt Enable Clear Register for Ij7am_hc_pipe3_phys__Ihc2_to_rc_vbusm_l0_j7am_128b_m2m_retime_dst_edc_ctrl_busecc_pend (access R/W1TC)
  [8] IJ7AM_HC_PIPE3_PHYS__IHC2_TO_RC_VBUSM_L0_J7AM_128B_M2M_RETIME_SRC_EDC_CTRL_BUSECC_ENABLE_CLR — Interrupt Enable Clear Register for Ij7am_hc_pipe3_phys__Ihc2_to_rc_vbusm_l0_j7am_128b_m2m_retime_src_edc_ctrl_busecc_pend (access R/W1TC)
  [7] J7AM_HC2_CBASS_EXPORT_J7AM_RC_TO_HC2_VBUSM_L1_M2M_BRIDGE_J7AM_HC2_CBASS_EXPORT_J7AM_RC_TO_HC2_VBUSM_L1_M2M_BRIDGE_SRC_EDC_CTRL_BUSECC_ENABLE_CLR — Interrupt Enable Clear Register for j7am_hc2_cbass_export_j7am_rc_to_hc2_vbusm_l1_m2m_bridge_j7am_hc2_cbass_export_j7am_rc_to_hc2_vbusm_l1_m2m_bridge_src_edc_ctrl_busecc_pend (access R/W1TC)
  [6] J7AM_HC2_CBASS_EXPORT_J7AM_HC2_TO_RC_VBUSM_L0_M2M_BRIDGE_J7AM_HC2_CBASS_EXPORT_J7AM_HC2_TO_RC_VBUSM_L0_M2M_BRIDGE_SRC_EDC_CTRL_BUSECC_ENABLE_CLR — Interrupt Enable Clear Register for j7am_hc2_cbass_export_j7am_hc2_to_rc_vbusm_l0_m2m_bridge_j7am_hc2_cbass_export_j7am_hc2_to_rc_vbusm_l0_m2m_bridge_src_edc_ctrl_busecc_pend (access R/W1TC)
  [5] J7AM_HC2_CBASS_SCRM_128B_CLK1_SCR_J7AM_HC2_CBASS_SCRM_128B_CLK1_SCR_EDC_CTRL_BUSECC_1_ENABLE_CLR — Interrupt Enable Clear Register for j7am_hc2_cbass_scrm_128b_clk1_scr_j7am_hc2_cbass_scrm_128b_clk1_scr_edc_ctrl_busecc_1_pend (access R/W1TC)
  [4] J7AM_HC2_CBASS_ERR_SCR_J7AM_HC2_CBASS_ERR_SCR_EDC_CTRL_BUSECC_ENABLE_CLR — Interrupt Enable Clear Register for j7am_hc2_cbass_err_scr_j7am_hc2_cbass_err_scr_edc_ctrl_busecc_pend (access R/W1TC)
  [3] J7AM_HC2_CBASS_CBASS_DEFAULT_MMRS_J7AM_HC2_CBASS_CBASS_DEFAULT_MMRS_EDC_CTRL_BUSECC_ENABLE_CLR — Interrupt Enable Clear Register for j7am_hc2_cbass_cbass_default_mmrs_j7am_hc2_cbass_cbass_default_mmrs_edc_ctrl_busecc_pend (access R/W1TC)
  [2] IJ7AM_MAIN_HC2_FW_CBASS_0_J7AM_MAIN_HC2_FW_CBASS_MAIN_SYSCLK0_4_CLK_EDC_CTRL_CBASS_INT_MAIN_SYSCLK0_4_BUSECC_ENABLE_CLR — Interrupt Enable Clear Register for Ij7am_main_hc2_fw_cbass_0_j7am_main_hc2_fw_cbass_main_SYSCLK0_4_clk_edc_ctrl_cbass_int_main_SYSCLK0_4_busecc_pend (access R/W1TC)
  [1] J7AM_MAIN_HC2_FW_CBASS_HC2_CBASS_DMSC_SLV_P2P_BRIDGE_HC2_CBASS_DMSC_SLV_BRIDGE_SRC_BUSECC_ENABLE_CLR — Interrupt Enable Clear Register for j7am_main_hc2_fw_cbass_hc2_cbass_dmsc_slv_p2p_bridge_hc2_cbass_dmsc_slv_bridge_src_busecc_pend (access R/W1TC)
  [0] J7AM_HC2_CBASS_CBASS_INT_DMSC_SCR_J7AM_HC2_CBASS_CBASS_INT_DMSC_SCR_EDC_CTRL_BUSECC_ENABLE_CLR — Interrupt Enable Clear Register for j7am_hc2_cbass_cbass_int_dmsc_scr_j7am_hc2_cbass_cbass_int_dmsc_scr_edc_ctrl_busecc_pend (access R/W1TC)
0x13C REGS_ded_eoi_reg — EOI Register
  [0] EOI_WR — EOI Register (access R/W1TS)
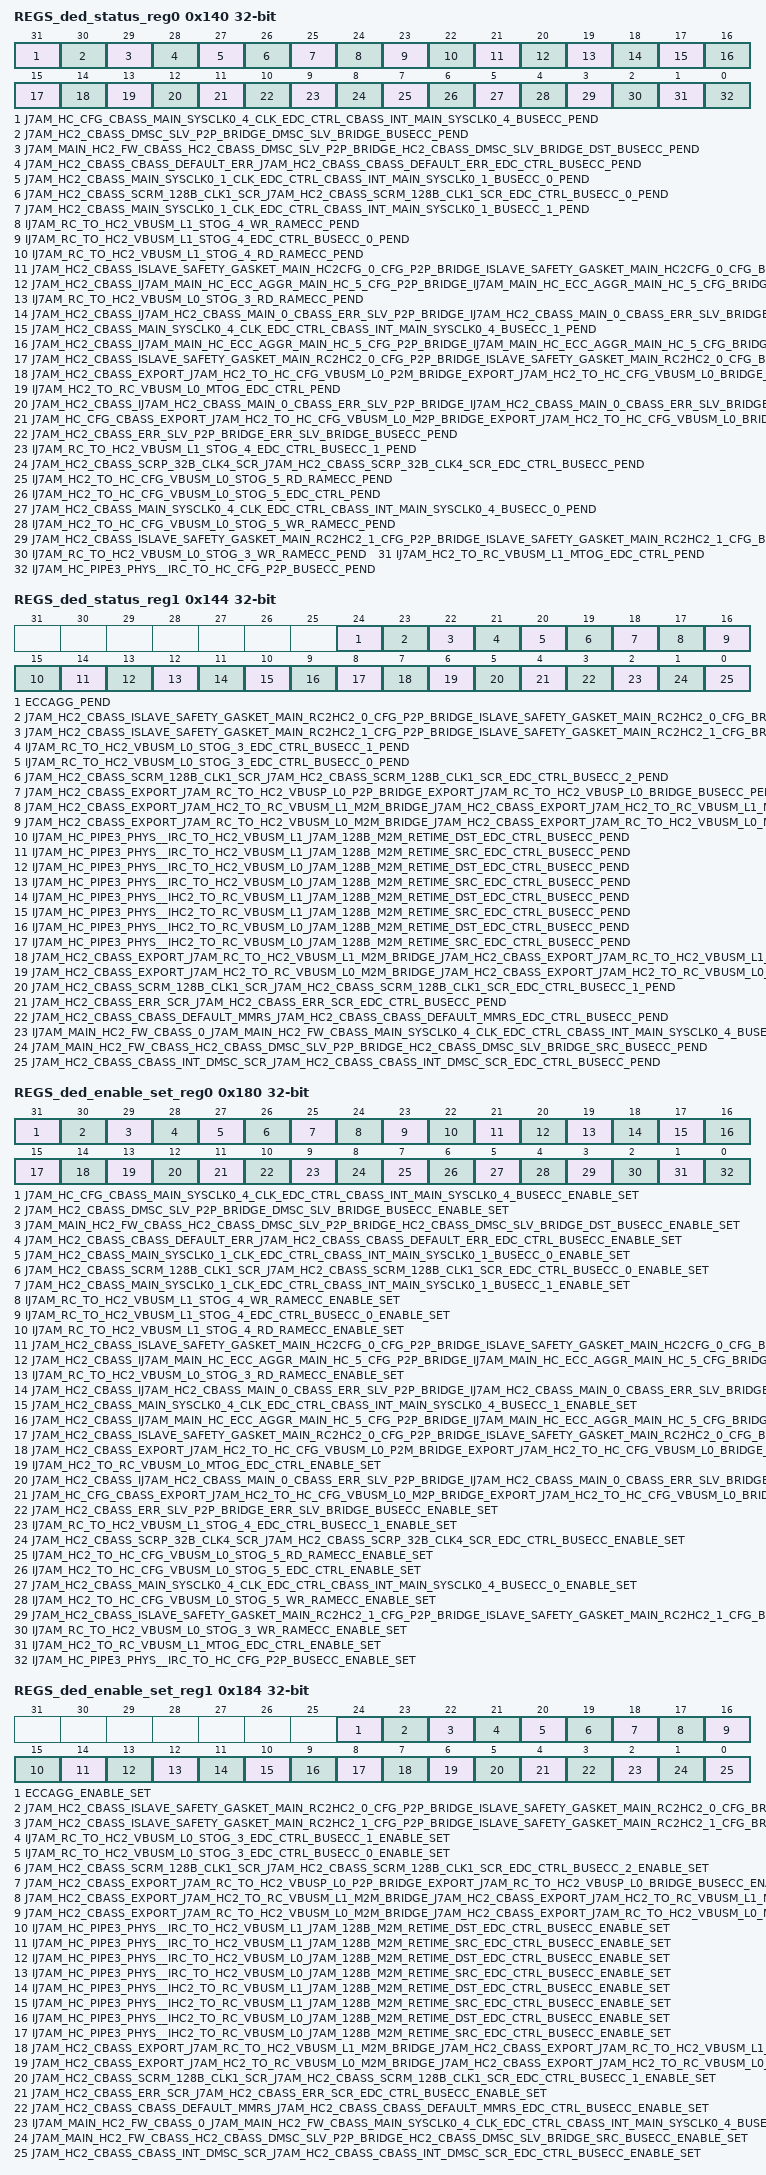
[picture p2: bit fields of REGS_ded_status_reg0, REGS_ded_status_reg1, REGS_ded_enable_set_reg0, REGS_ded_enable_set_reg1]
0x140 REGS_ded_status_reg0 — Interrupt Status Register 0
  fields as REGS_sec_status_reg0
0x144 REGS_ded_status_reg1 — Interrupt Status Register 1
  fields as REGS_sec_status_reg1
0x180 REGS_ded_enable_set_reg0 — Interrupt Enable Set Register 0
  fields as REGS_sec_enable_set_reg0
0x184 REGS_ded_enable_set_reg1 — Interrupt Enable Set Register 1
  fields as REGS_sec_enable_set_reg1
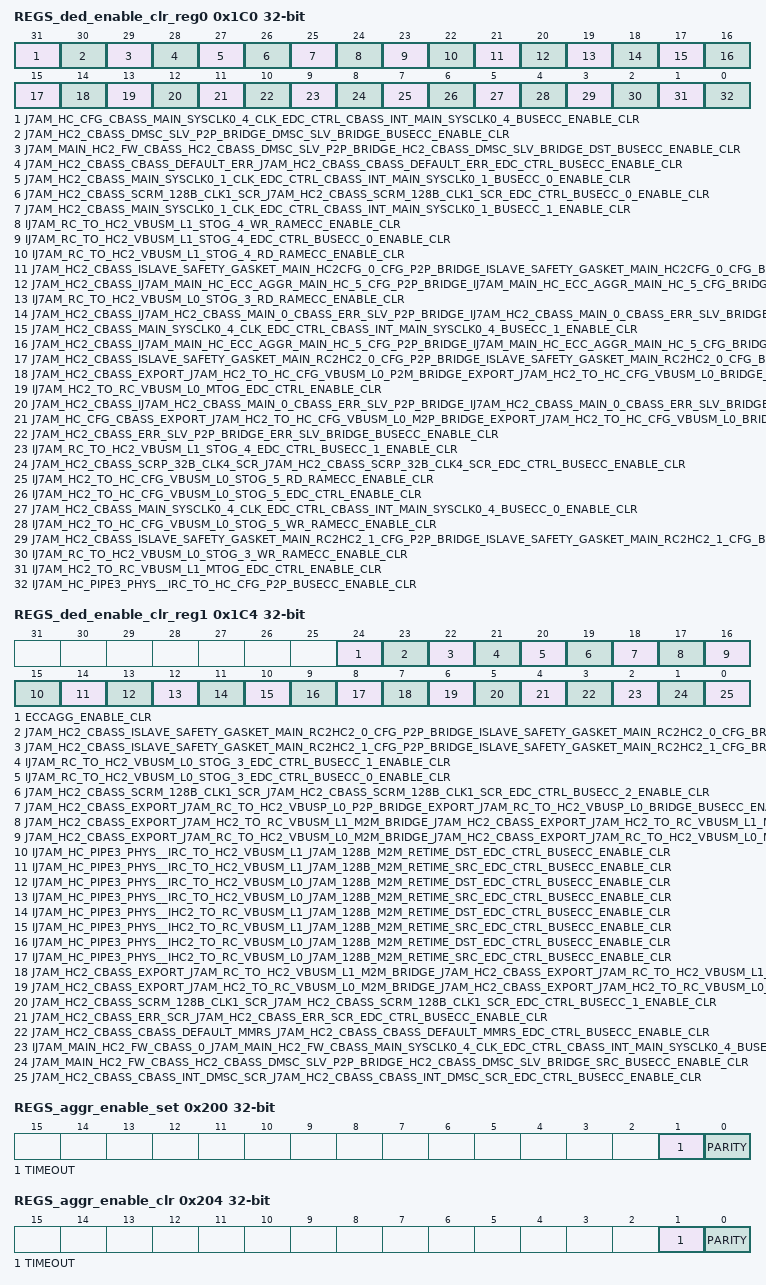
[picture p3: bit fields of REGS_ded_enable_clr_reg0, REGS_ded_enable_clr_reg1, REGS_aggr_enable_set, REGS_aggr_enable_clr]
0x1C0 REGS_ded_enable_clr_reg0 — Interrupt Enable Clear Register 0
  fields as REGS_sec_enable_clr_reg0
0x1C4 REGS_ded_enable_clr_reg1 — Interrupt Enable Clear Register 1
  fields as REGS_sec_enable_clr_reg1
0x200 REGS_aggr_enable_set — AGGR interrupt enable set Register
  [1] TIMEOUT — interrupt enable set for svbus timeout errors (access R/W1TS)
  [0] PARITY — interrupt enable set for parity errors (access R/W1TS)
0x204 REGS_aggr_enable_clr — AGGR interrupt enable clear Register
  [1] TIMEOUT — interrupt enable clear for svbus timeout errors (access R/W1TC)
  [0] PARITY — interrupt enable clear for parity errors (access R/W1TC)
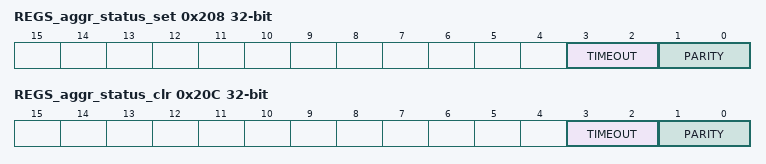
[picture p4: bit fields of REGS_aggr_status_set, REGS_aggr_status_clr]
0x208 REGS_aggr_status_set — AGGR interrupt status set Register
  [3:2] TIMEOUT — interrupt status set for svbus timeout errors (access R/WI)
  [1:0] PARITY — interrupt status set for parity errors (access R/WI)
0x20C REGS_aggr_status_clr — AGGR interrupt status clear Register
  [3:2] TIMEOUT — interrupt status clear for svbus timeout errors (access R/WD)
  [1:0] PARITY — interrupt status clear for parity errors (access R/WD)
